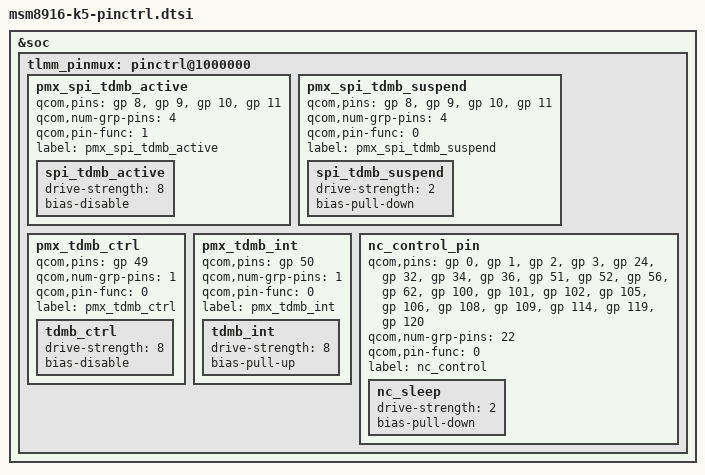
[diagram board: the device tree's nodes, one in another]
/* Copyright (c) 2013-2014, The Linux Foundation. All rights reserved.
 *
 * This program is free software; you can redistribute it and/or modify
 * it under the terms of the GNU General Public License version 2 and
 * only version 2 as published by the Free Software Foundation.
 *
 * This program is distributed in the hope that it will be useful,
 * but WITHOUT ANY WARRANTY; without even the implied warranty of
 * MERCHANTABILITY or FITNESS FOR A PARTICULAR PURPOSE.  See the
 * GNU General Public License for more details.
 */

#include "../msm8916-k5-common/msm8916-k5-common-pinctrl.dtsi"

&soc {
	tlmm_pinmux: pinctrl@1000000 {

		pmx_spi_tdmb_active {
			qcom,pins =  <&gp 8>, <&gp 9>, <&gp 10>, <&gp 11>;
			qcom,num-grp-pins = <4>;
			qcom,pin-func = <1>;
			label = "pmx_spi_tdmb_active";
			spi_tdmb_active: spi_tdmb_active {
				drive-strength = <8>; /* 8MA */
				bias-disable;
				};
			};
		pmx_spi_tdmb_suspend {
			qcom,pins =  <&gp 8>, <&gp 9>, <&gp 10>, <&gp 11>;
			qcom,num-grp-pins = <4>;
			qcom,pin-func = <0>;
			label = "pmx_spi_tdmb_suspend";
			spi_tdmb_suspend: spi_tdmb_suspend {
				drive-strength = <2>; /* 2MA */
				bias-pull-down;
				};
			};
		pmx_tdmb_ctrl {
			qcom,pins = <&gp 49>;
			qcom,num-grp-pins = <1>;
			qcom,pin-func = <0>;
			label = "pmx_tdmb_ctrl";
			tdmb_ctrl: tdmb_ctrl {
				drive-strength = <8>; /* 8MA */
				bias-disable;
				};
			};
		pmx_tdmb_int {
			qcom,pins = <&gp 50>;
			qcom,num-grp-pins = <1>;
			qcom,pin-func = <0>;
			label = "pmx_tdmb_int";
			tdmb_int: tdmb_int {
				drive-strength = <8>; /* 8MA */
				bias-pull-up;
				};
			};

        /* NC gpio config */
        nc_control_pin {
            qcom,pins = <&gp 0>, <&gp 1>, <&gp 2>,
                <&gp 3>, <&gp 24>, <&gp 32>, <&gp 34>,
                <&gp 36>, <&gp 51>, <&gp 52>, <&gp 56>, <&gp 62>,
                <&gp 100>, <&gp 101>, <&gp 102>, <&gp 105>, <&gp 106>,
                <&gp 108>, <&gp 109>, <&gp 114>, <&gp 119>, <&gp 120>;
            qcom,num-grp-pins = <22>;
            qcom,pin-func = <0>;
            label = "nc_control";
            nc_sleep: nc_sleep {
                drive-strength = <2>;
                bias-pull-down;
            };
        };

	};
};
